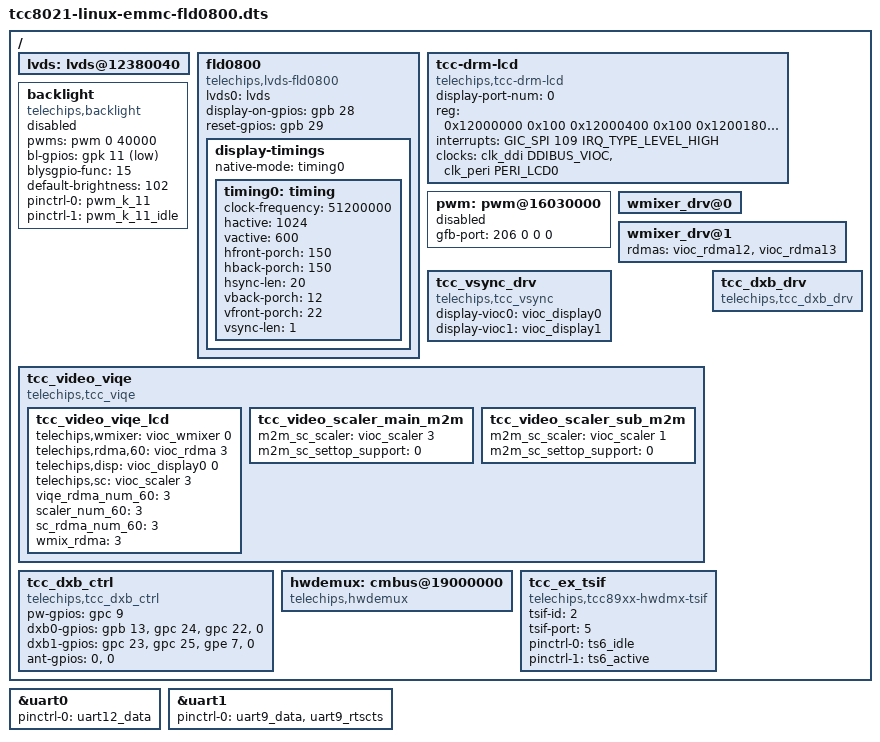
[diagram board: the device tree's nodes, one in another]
/*
 * Device tree for Telechips TCC8020 AVN board
 *
 * Copyright (C) 2016 Telechips Inc. - http://www.telechips.com
 *
 * This file is dual-licensed: you can use it either under the terms
 * of the GPL or the X11 license, at your option. Note that this dual
 * licensing only applies to this file, and not this project as a
 * whole.
 *
 *  a) This file is free software; you can redistribute it and/or
 *     modify it under the terms of the GNU General Public License as
 *     published by the Free Software Foundation; either version 2 of the
 *     License, or (at your option) any later version.
 *
 *     This file is distributed in the hope that it will be useful,
 *     but WITHOUT ANY WARRANTY; without even the implied warranty of
 *     MERCHANTABILITY or FITNESS FOR A PARTICULAR PURPOSE.  See the
 *     GNU General Public License for more details.
 *
 * Or, alternatively,
 *
 *  b) Permission is hereby granted, free of charge, to any person
 *     obtaining a copy of this software and associated documentation
 *     files (the "Software"), to deal in the Software without
 *     restriction, including without limitation the rights to use,
 *     copy, modify, merge, publish, distribute, sublicense, and/or
 *     sell copies of the Software, and to permit persons to whom the
 *     Software is furnished to do so, subject to the following
 *     conditions:
 *
 *     The above copyright notice and this permission notice shall be
 *     included in all copies or substantial portions of the Software.
 *
 *     THE SOFTWARE IS PROVIDED "AS IS", WITHOUT WARRANTY OF ANY KIND,
 *     EXPRESS OR IMPLIED, INCLUDING BUT NOT LIMITED TO THE WARRANTIES
 *     OF MERCHANTABILITY, FITNESS FOR A PARTICULAR PURPOSE AND
 *     NONINFRINGEMENT. IN NO EVENT SHALL THE AUTHORS OR COPYRIGHT
 *     HOLDERS BE LIABLE FOR ANY CLAIM, DAMAGES OR OTHER LIABILITY,
 *     WHETHER IN AN ACTION OF CONTRACT, TORT OR OTHERWISE, ARISING
 *     FROM, OUT OF OR IN CONNECTION WITH THE SOFTWARE OR THE USE OR
 *     OTHER DEALINGS IN THE SOFTWARE.
 */

/dts-v1/;

#include "tcc/tcc8021-linux-emmc.dtsi"

/ {
	lvds: lvds@12380040{
		status = "okay";
	};

	fld0800 {
		compatible = "telechips,lvds-fld0800";
		status = "okay";
		lvds0 = <&lvds>;
		//power-on-gpios = ;                // LCD_ON
		display-on-gpios = <&gpb 28 0>;     // LCD_DISP
		reset-gpios = <&gpb 29 0>;          // LCD_RST
		//lvds-stby-gpios = <&gpb 19 0>;      // LCD_DE = LVDS_STBY in LVDS
		//lvds-power-gpios = ;              // LVDS_EN
		//lvds-power-gpios1 = ;             // V_5V0_EN

		display-timings {
			native-mode = <&timing0>;
			timing0: timing {
				clock-frequency = <51200000>;
				hactive = <1024>;
				vactive = <600>;
				hfront-porch = <150>;
				hback-porch = <150>;
				hsync-len = <20>;
				vback-porch = <12>;
				vfront-porch = <22>;
				vsync-len = <1>;
			};
		};
	};

	tcc-drm-lcd {
		compatible = "telechips,tcc-drm-lcd";
		display-port-num = <0>;
		reg = <0x12000000 0x100 0x12000400 0x100 0x12001800 0x100 0x1200a000 0x800>;
		reg-names = "ddc", "rdma", "wmix", "vioc";
		interrupts = <GIC_SPI 109 IRQ_TYPE_LEVEL_HIGH>;
		interrupt-names = "vsync";
		clock-names = "ddibus_vioc", "peri_lcd0";
		clocks = <&clk_ddi DDIBUS_VIOC>, <&clk_peri PERI_LCD0>;
		status = "okay";
	};

	pwm: pwm@16030000 {
		status = "disabled";
		/* Port A, B, C, D, GFB Number */
		gfb-port = <206 0 0 0>;
	};

	backlight {
		compatible = "telechips,backlight";
		pwms = <&pwm 0 40000>;  /* unit:nsec. */
		bl-gpios = <&gpk 11 1>;
		blysgpio-func = <15>;
		default-brightness = <102>; /* MAX:255 */
		pinctrl-names = "active", "idle";
		pinctrl-0 = <&pwm_k_11>;
		pinctrl-1 = <&pwm_k_11_idle>;
		status = "disabled";
	};

	wmixer_drv@0 {
		status = "okay";
	};

	wmixer_drv@1 {
		rdmas = <&vioc_rdma12>, <&vioc_rdma13>;
		status = "okay";
	};

	tcc_vsync_drv {
		compatible = "telechips,tcc_vsync";
		display-vioc0 = <&vioc_display0>;
		display-vioc1 = <&vioc_display1>;
		status = "okay";
	};

	tcc_video_viqe {
		compatible = "telechips,tcc_viqe";
		status ="okay";

		tcc_video_viqe_lcd {
			telechips,wmixer = <&vioc_wmixer 0>;
			telechips,rdma,60 = <&vioc_rdma 3>;
			telechips,disp = <&vioc_display0 0>;
			telechips,sc = <&vioc_scaler 3>;
			viqe_rdma_num_60 = <3>;
			scaler_num_60 = <3>;
			sc_rdma_num_60 = <3>;
			wmix_rdma = <3>;
		};

		tcc_video_scaler_main_m2m {
			m2m_sc_scaler = <&vioc_scaler 3>;	/* id:3, path:17 */
			m2m_sc_settop_support = <0>;
		};

		tcc_video_scaler_sub_m2m {
			m2m_sc_scaler = <&vioc_scaler 1>;	/* id:1, path:7 */
			m2m_sc_settop_support = <0>;
		};
	};

	tcc_dxb_drv {
		compatible = "telechips,tcc_dxb_drv";
	};

	tcc_dxb_ctrl {
		compatible = "telechips,tcc_dxb_ctrl";
		pw-gpios   = <&gpc 9 0>;
		dxb0-gpios = <&gpb 13 0>, <&gpc 24 0>, <&gpc 22 0>, <0>;
		dxb1-gpios = <&gpc 23 0>, <&gpc 25 0>, <&gpe 7 0>, <0>;
		ant-gpios  = <0>, <0>;
	};

	/* H/W Demux */
	hwdemux: cmbus@19000000 {
		compatible = "telechips,hwdemux";
		status = "okay";
	};

	tcc_ex_tsif {
		compatible = "telechips,tcc89xx-hwdmx-tsif";
		tsif-id = <2>;
		tsif-port = <5>;
		pinctrl-names = "idle", "active";
		pinctrl-0 = <&ts6_idle>;
		pinctrl-1 = <&ts6_active>;
	};
};

&uart0 {
	pinctrl-names = "default";
	pinctrl-0 = <&uart12_data>;
	status = "okay";
};

&uart1 {
	pinctrl-names = "default";
	pinctrl-0 = <&uart9_data &uart9_rtscts>;
	status = "okay";
};
